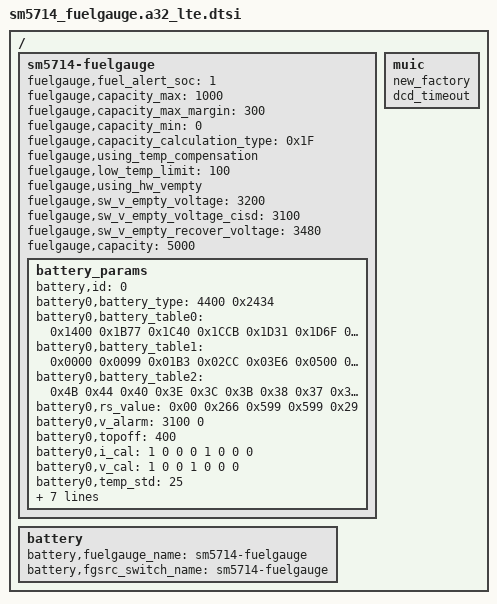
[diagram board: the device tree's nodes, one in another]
/*
 * Vogue battery device tree common
 *
 * Copyright (c) 2018 Samsung Electronics Co., Ltd.
 *		http://www.samsung.com
 *
 * This program is free software; you can redistribute it and/or modify
 * it under the terms of the GNU General Public License version 2 as
 * published by the Free Software Foundation.
 */

/ {
	fragment@smd {
		target-path = "/";
		__overlay__ {
			sm5714-fuelgauge {
				status = "okay";
				fuelgauge,fuel_alert_soc = <1>;
				fuelgauge,capacity_max = <1000>;
				fuelgauge,capacity_max_margin = <300>;
				fuelgauge,capacity_min = <0>;
				fuelgauge,capacity_calculation_type = <0x1F>;
				fuelgauge,using_temp_compensation;
				fuelgauge,low_temp_limit = <100>;
				fuelgauge,using_hw_vempty;
				fuelgauge,sw_v_empty_voltage = <3200>;
				fuelgauge,sw_v_empty_voltage_cisd = <3100>;
				fuelgauge,sw_v_empty_recover_voltage = <3480>;
				fuelgauge,capacity = <5000>;
				battery_params {
					battery,id = <0>;
					battery0,battery_type = <4400 0x2434>; /* batt_v_max, cap */
					battery0,battery_table0 = <
						0x1400 0x1B77 0x1C40 0x1CCB 0x1D31 0x1D6F 0x1D81 0x1D88
						0x1DA0 0x1DE3 0x1E1F 0x1E45 0x1E5E 0x1E7E 0x1EA7 0x1EDC
						0x1EFE 0x1F7C 0x1FCC 0x2054 0x20BB 0x2144 0x223E 0x2400
						>;
					battery0,battery_table1 = <
						0x0000 0x0099 0x01B3 0x02CC 0x03E6 0x0500 0x07B3 0x0A80
						0x0D4C 0x12CC 0x1B19 0x2099 0x2619 0x2B99 0x3133 0x36B3
						0x3980 0x3F00 0x4480 0x4CCC 0x524C 0x58E6 0x6400 0x6419
						>;
					battery0,battery_table2 = <
						0x4B 0x44 0x40 0x3E 0x3C 0x3B 0x38 0x37
						0x35 0x34 0x34 0x33 0x33 0x33 0x33 0x32
						>;
					/* spare factor chg_factor dischg_factor manvalue */
					battery0,rs_value = <0x00 0x266 0x599 0x599 0x29>;
					battery0,v_alarm = <3100 0>;
					battery0,topoff = <400>;
					battery0,i_cal = <1 0 0 0 1 0 0 0 >;
					battery0,v_cal = <1 0 0 1 0 0 0>;
					battery0,temp_std = <25>;
					battery0,tem_poff = <3400 50 3250 50>;
					battery0,aux_ctrl = <0x303>;
					battery0,data_ver = <1>;
					battery0,v_max_table = <0x223E 0x221C 0x21FA 0x21D9 0x2184>;
					battery0,q_max_table = <0x2434 0x23A8 0x231D 0x2291 0x2134>;
				};
			};

			battery {
				battery,fuelgauge_name = "sm5714-fuelgauge";
				battery,fgsrc_switch_name = "sm5714-fuelgauge";
			};

			muic {
				new_factory;
				dcd_timeout;
			};
		};
	};
};
